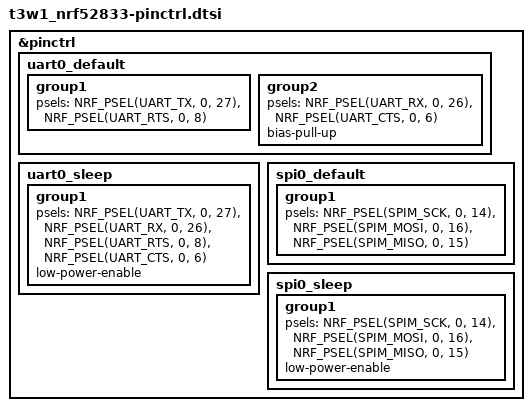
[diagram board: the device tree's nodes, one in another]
/*
 * Copyright (c) 2022 Nordic Semiconductor
 * SPDX-License-Identifier: Apache-2.0
 */

&pinctrl {
	uart0_default: uart0_default {
		group1 {
			psels = <NRF_PSEL(UART_TX, 0, 27)>,
				<NRF_PSEL(UART_RTS, 0, 8)>;
		};
		group2 {
			psels = <NRF_PSEL(UART_RX, 0, 26)>,
				<NRF_PSEL(UART_CTS, 0, 6)>;
			bias-pull-up;
		};
	};

	uart0_sleep: uart0_sleep {
		group1 {
			psels = <NRF_PSEL(UART_TX, 0, 27)>,
				<NRF_PSEL(UART_RX, 0, 26)>,
				<NRF_PSEL(UART_RTS, 0, 8)>,
				<NRF_PSEL(UART_CTS, 0, 6)>;
			low-power-enable;
		};
	};


	spi0_default: spi0_default {
		group1 {
			psels = <NRF_PSEL(SPIM_SCK, 0, 14)>,
				<NRF_PSEL(SPIM_MOSI, 0, 16)>,
				<NRF_PSEL(SPIM_MISO, 0, 15)>;
		};
	};

	spi0_sleep: spi0_sleep {
		group1 {
			psels = <NRF_PSEL(SPIM_SCK, 0, 14)>,
				<NRF_PSEL(SPIM_MOSI, 0, 16)>,
				<NRF_PSEL(SPIM_MISO, 0, 15)>;
			low-power-enable;
		};
	};


};
